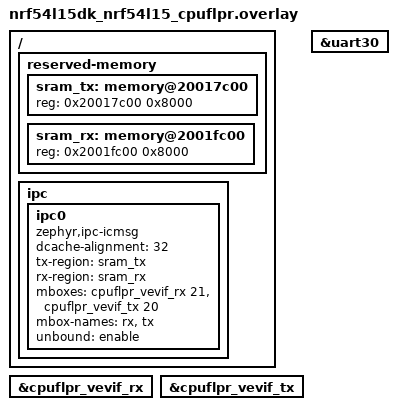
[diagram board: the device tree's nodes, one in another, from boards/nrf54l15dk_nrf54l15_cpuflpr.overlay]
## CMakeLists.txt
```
#
# Copyright (c) 2025 Nordic Semiconductor ASA
#
# SPDX-License-Identifier: LicenseRef-Nordic-5-Clause
#

cmake_minimum_required(VERSION 3.20.0)

find_package(Zephyr REQUIRED HINTS $ENV{ZEPHYR_BASE})
project(remote)

target_sources(app PRIVATE src/main.c)
```

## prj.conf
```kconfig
CONFIG_IPC_SERVICE=y
CONFIG_MBOX=y

CONFIG_HEAP_MEM_POOL_SIZE=2048
CONFIG_MAIN_STACK_SIZE=2048

CONFIG_LOG=y
CONFIG_LOG_BUFFER_SIZE=8192
#CONFIG_LOG_MODE_MINIMAL=y
# Enable for debugging purposes only
#CONFIG_SERIAL=n
#CONFIG_LOG=n
#CONFIG_LOG_MODE_DEFERRED=n
#CONFIG_CONSOLE=n
#CONFIG_UART_CONSOLE=n
```

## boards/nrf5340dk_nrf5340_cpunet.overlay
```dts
/*
 * Copyright (c) 2026 Nordic Semiconductor ASA
 *
 * SPDX-License-Identifier: LicenseRef-Nordic-5-Clause
 */

/delete-node/ &ipc0;
/delete-node/ &sram0_shared;

/ {
	chosen {
		/delete-property/ zephyr,ipc_shm;
	};

	reserved-memory {
		#address-cells = <1>;
		#size-cells = <1>;
		ranges;

		sram_rx: memory@20070000 {
			reg = <0x20070000 0x8000>;
		};

		sram_tx: memory@20078000 {
			reg = <0x20078000 0x8000>;
		};
	};

	ipc0: ipc0 {
		compatible = "zephyr,ipc-icmsg";
		tx-region = <&sram_tx>;
		rx-region = <&sram_rx>;
		mboxes = <&mbox 0>, <&mbox 1>;
		mbox-names = "rx", "tx";
		unbound = "enable";
		dcache-alignment = <0x20>;
		status = "okay";
	};
};
```

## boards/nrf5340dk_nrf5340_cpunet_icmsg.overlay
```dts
/*
 * Copyright (c) 2026 Nordic Semiconductor ASA
 *
 * SPDX-License-Identifier: LicenseRef-Nordic-5-Clause
 */

&ipc0 {
	compatible = "zephyr,ipc-icmsg";
	/delete-property/ tx-blocks;
	/delete-property/ rx-blocks;
};
```

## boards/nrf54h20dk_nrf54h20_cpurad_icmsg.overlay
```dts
/*
 * Copyright (c) 2026 Nordic Semiconductor ASA
 *
 * SPDX-License-Identifier: LicenseRef-Nordic-5-Clause
 */

&ipc0 {
	compatible = "zephyr,ipc-icmsg";
	unbound = "enable";
	/delete-property/ tx-blocks;
	/delete-property/ rx-blocks;
};
```

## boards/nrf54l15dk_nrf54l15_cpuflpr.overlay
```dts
/*
 * Copyright (c) 2026 Nordic Semiconductor ASA
 *
 * SPDX-License-Identifier: LicenseRef-Nordic-5-Clause
 */

/ {
	reserved-memory {
		#address-cells = <1>;
		#size-cells = <1>;
		ranges;

		sram_tx: memory@20017c00 {
			reg = <0x20017c00 0x8000>;
		};

		sram_rx: memory@2001fc00 {
			reg = <0x2001fc00 0x8000>;
		};
	};

	ipc {
		ipc0: ipc0 {
			compatible = "zephyr,ipc-icmsg";
			/delete-property/ tx-blocks;
			/delete-property/ rx-blocks;
			dcache-alignment = <32>;
			tx-region = <&sram_tx>;
			rx-region = <&sram_rx>;
			mboxes = <&cpuflpr_vevif_rx 21>, <&cpuflpr_vevif_tx 20>;
			mbox-names = "rx", "tx";
			unbound = "enable";
			status = "okay";
		};
	};
};

&cpuflpr_vevif_rx {
	status = "okay";
};

&cpuflpr_vevif_tx {
	status = "okay";
};

&uart30 {
	/delete-property/ hw-flow-control;
};
```

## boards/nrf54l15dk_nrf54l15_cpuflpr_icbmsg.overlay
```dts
/*
 * Copyright (c) 2026 Nordic Semiconductor ASA
 *
 * SPDX-License-Identifier: LicenseRef-Nordic-5-Clause
 */

/ {
	reserved-memory {
		#address-cells = <1>;
		#size-cells = <1>;
		ranges;

		sram_tx: memory@20026c00 {
			reg = <0x20026c00 DT_SIZE_K(2)>;
		};

		sram_rx: memory@20027400 {
			reg = <0x20027400 DT_SIZE_K(2)>;
		};
	};

	ipc {
		ipc0: ipc0 {
			compatible = "zephyr,ipc-icbmsg";
			dcache-alignment = <32>;
			tx-region = <&sram_tx>;
			rx-region = <&sram_rx>;
			tx-blocks = <18>;
			rx-blocks = <16>;
			mboxes = <&cpuflpr_vevif_rx 21>, <&cpuflpr_vevif_tx 20>;
			mbox-names = "rx", "tx";
			unbound = "enable";
			status = "okay";
		};
	};
};

&cpuflpr_vevif_rx {
	status = "okay";
};

&cpuflpr_vevif_tx {
	status = "okay";
};

&uart30 {
	/delete-property/ hw-flow-control;
};
```

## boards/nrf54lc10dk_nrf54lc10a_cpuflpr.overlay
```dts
/*
 * Copyright (c) 2026 Nordic Semiconductor ASA
 *
 * SPDX-License-Identifier: LicenseRef-Nordic-5-Clause
 */

/ {
	reserved-memory {
		#address-cells = <1>;
		#size-cells = <1>;
		ranges;

		sram_tx: memory@2000fc00 {
			reg = <0x2000fc00 0x8000>;
		};

		sram_rx: memory@20017c00 {
			reg = <0x20017c00 0x8000>;
		};
	};

	ipc {
		ipc0: ipc0 {
			compatible = "zephyr,ipc-icmsg";
			dcache-alignment = <32>;
			/delete-property/ tx-blocks;
			/delete-property/ rx-blocks;
			tx-region = <&sram_tx>;
			rx-region = <&sram_rx>;
			mboxes = <&cpuflpr_vevif_rx 21>, <&cpuflpr_vevif_tx 20>;
			mbox-names = "rx", "tx";
			unbound = "enable";
			status = "okay";
		};
	};
};

&cpuflpr_vevif_rx {
	status = "okay";
};

&cpuflpr_vevif_tx {
	status = "okay";
};

&uart20 {
	/delete-property/ hw-flow-control;
};
```

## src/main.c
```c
/*
 * Copyright (c) 2025, Nordic Semiconductor ASA
 *
 * SPDX-License-Identifier: LicenseRef-Nordic-5-Clause
 */

#include <zephyr/kernel.h>
#include <zephyr/device.h>
#include <zephyr/ipc/ipc_service.h>

#define BOUND_TIMEOUT_MS 8000

const struct device *ipc0_instance = DEVICE_DT_GET(DT_NODELABEL(ipc0));
static struct ipc_ept test_endpoint;

K_SEM_DEFINE(endpoint_bound_sem, 0, 1);
K_SEM_DEFINE(endpoint_unbound_sem, 0, 1);

static void ep_bound_callback(void *priv)
{
	k_sem_give(&endpoint_bound_sem);
}

static void ep_unbound_callback(void *priv)
{
	k_sem_give(&endpoint_unbound_sem);
}

static void ep_recv_callback(const void *data, size_t len, void *priv)
{
	int ret;

	ret = ipc_service_send(&test_endpoint, data, len);
	if (ret < 0) {
		printk("Failed to send data back: %d\n", ret);
	}
}

static void ep_error_callback(const char *message, void *priv)
{
	printk("IPC data error: %s\n", message);
}

static struct ipc_ept_cfg test_ep_cfg = {
	.name = "ep0",
	.cb = {
		.bound = ep_bound_callback,
		.unbound = ep_unbound_callback,
		.received = ep_recv_callback,
		.error = ep_error_callback,
	},
};

static void configure_ipc(struct ipc_ept *endpoint)
{
	int ret;

	ret = ipc_service_open_instance(ipc0_instance);
	if ((ret < 0) && (ret != -EALREADY)) {
		printk("IPC instance open failed\n");
	} else {
		printk("Instance opened\n");
	}

	ret = ipc_service_register_endpoint(ipc0_instance, endpoint, &test_ep_cfg);
	if (ret) {
		printk("IPC endpoint register failed\n");
	} else {
		printk("Endpoint registered\n");
	}

	printk("Waiting for binding\n");
	ret = k_sem_take(&endpoint_bound_sem, K_MSEC(BOUND_TIMEOUT_MS));
	if (ret) {
		printk("IPC timeout occurred while waiting for endpoint bound\n");
	} else {
		printk("IPC endpoint bound\n");
	}

	k_msleep(10);
}

int main(void)
{
	printk("Hello\n");
	k_msleep(50);

	configure_ipc(&test_endpoint);

	while (1) {
		if (k_sem_take(&endpoint_unbound_sem, K_NO_WAIT) == 0) {
			printk("Endpoint unbounded\n");
			printk("Reconnecting\n");
			configure_ipc(&test_endpoint);
		}
		k_msleep(103);
	}

	return 0;
}
```
